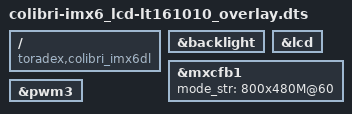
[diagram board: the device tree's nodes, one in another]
// SPDX-License-Identifier: GPL-2.0-or-later OR MIT
/*
 * Copyright 2020-2021 Toradex
 */

// Turn on the parallel RGB interface with setting for 7" Displays on the Colibri iMX6DL

/dts-v1/;
/plugin/;

/ {
	compatible = "toradex,colibri_imx6dl";
};

&backlight {
	status = "okay";
};

&lcd {
	status = "okay";
};

&mxcfb1 {
	mode_str ="800x480M@60";
	status = "okay";
};

&pwm3 {
	status = "okay";
};
